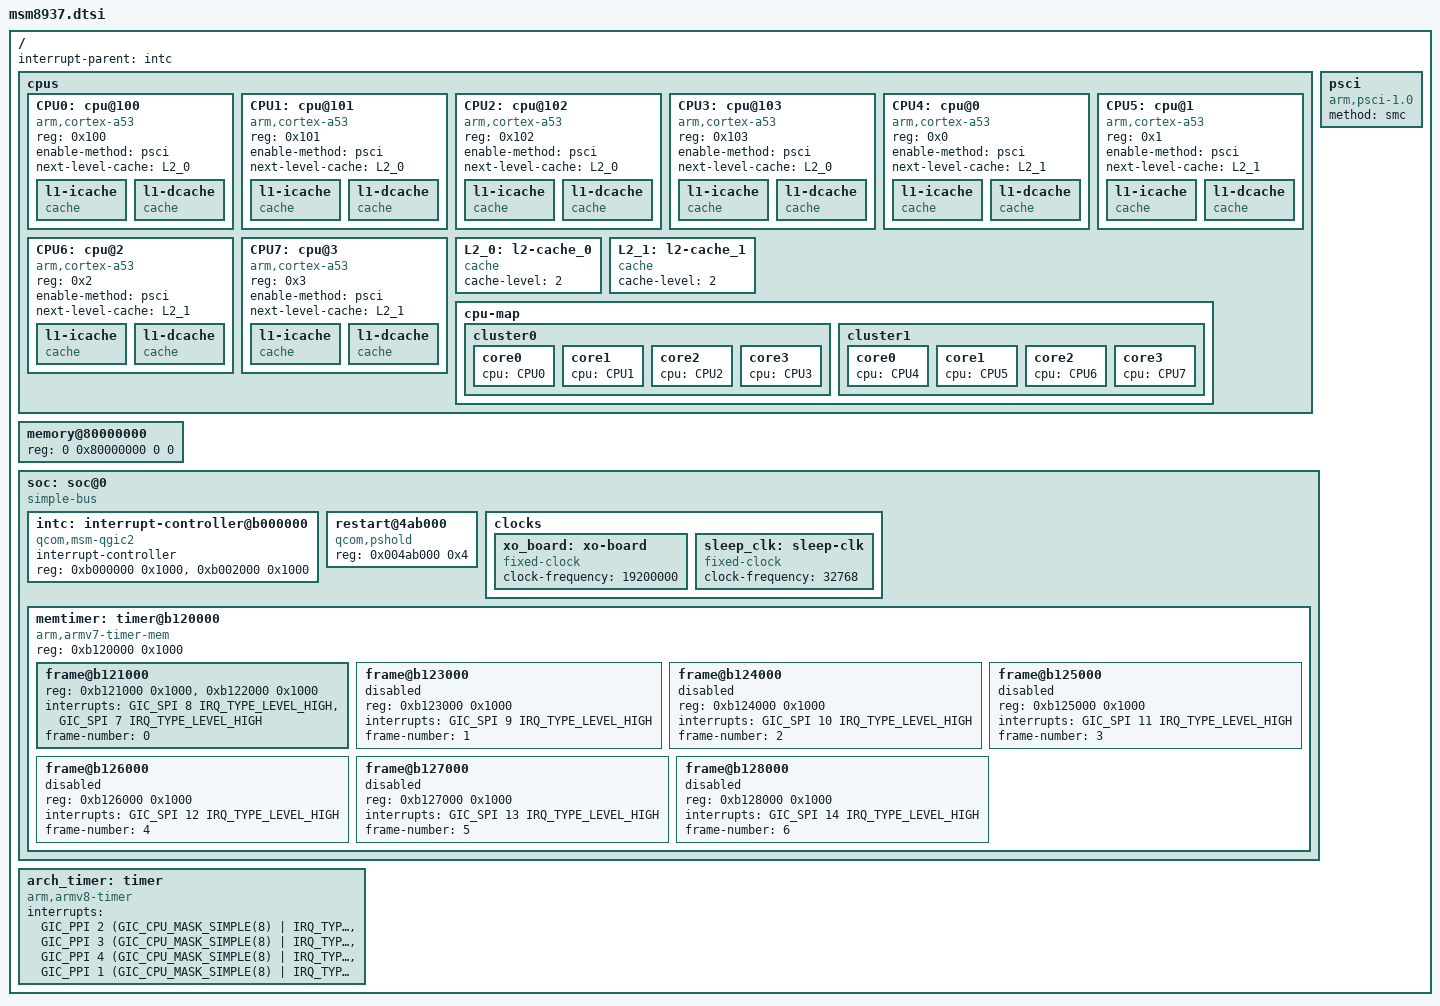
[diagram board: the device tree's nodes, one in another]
// SPDX-License-Identifier: BSD-3-Clause
/*
 * Copyright (c) 2023, Dang Huynh <danct12@riseup.net>
 */

#include <dt-bindings/interrupt-controller/arm-gic.h>

/ {
	interrupt-parent = <&intc>;

	#address-cells = <2>;
	#size-cells = <2>;

	cpus {
		#address-cells = <1>;
		#size-cells = <0>;

		CPU0: cpu@100 {
			device_type = "cpu";
			compatible = "arm,cortex-a53";
			reg = <0x100>;
			enable-method = "psci";
			next-level-cache = <&L2_0>;
			l1-icache {
				compatible = "cache";
			};
			l1-dcache {
				compatible = "cache";
			};
		};

		CPU1: cpu@101 {
			device_type = "cpu";
			compatible = "arm,cortex-a53";
			reg = <0x101>;
			enable-method = "psci";
			next-level-cache = <&L2_0>;
			l1-icache {
				compatible = "cache";
			};
			l1-dcache {
				compatible = "cache";
			};
		};

		CPU2: cpu@102 {
			device_type = "cpu";
			compatible = "arm,cortex-a53";
			reg = <0x102>;
			enable-method = "psci";
			next-level-cache = <&L2_0>;
			l1-icache {
				compatible = "cache";
			};
			l1-dcache {
				compatible = "cache";
			};
		};

		CPU3: cpu@103 {
			device_type = "cpu";
			compatible = "arm,cortex-a53";
			reg = <0x103>;
			enable-method = "psci";
			next-level-cache = <&L2_0>;
			l1-icache {
				compatible = "cache";
			};
			l1-dcache {
				compatible = "cache";
			};
		};

		CPU4: cpu@0 {
			device_type = "cpu";
			compatible = "arm,cortex-a53";
			reg = <0x0>;
			enable-method = "psci";
			next-level-cache = <&L2_1>;
			l1-icache {
				compatible = "cache";
			};
			l1-dcache {
				compatible = "cache";
			};
		};

		CPU5: cpu@1 {
			device_type = "cpu";
			compatible = "arm,cortex-a53";
			reg = <0x1>;
			enable-method = "psci";
			next-level-cache = <&L2_1>;
			l1-icache {
				compatible = "cache";
			};
			l1-dcache {
				compatible = "cache";
			};
		};

		CPU6: cpu@2 {
			device_type = "cpu";
			compatible = "arm,cortex-a53";
			reg = <0x2>;
			enable-method = "psci";
			next-level-cache = <&L2_1>;
			l1-icache {
				compatible = "cache";
			};
			l1-dcache {
				compatible = "cache";
			};
		};

		CPU7: cpu@3 {
			device_type = "cpu";
			compatible = "arm,cortex-a53";
			reg = <0x3>;
			enable-method = "psci";
			next-level-cache = <&L2_1>;
			l1-icache {
				compatible = "cache";
			};
			l1-dcache {
				compatible = "cache";
			};
		};

		L2_0: l2-cache_0 {
			compatible = "cache";
			cache-level = <2>;
		};

		L2_1: l2-cache_1 {
			compatible = "cache";
			cache-level = <2>;
		};

		cpu-map {
			cluster0 {
				core0 {
					cpu = <&CPU0>;
				};

				core1 {
					cpu = <&CPU1>;
				};

				core2 {
					cpu = <&CPU2>;
				};

				core3 {
					cpu = <&CPU3>;
				};
			};

			cluster1 {
				core0 {
					cpu = <&CPU4>;
				};

				core1 {
					cpu = <&CPU5>;
				};

				core2 {
					cpu = <&CPU6>;
				};

				core3 {
					cpu = <&CPU7>;
				};
			};
		};
	};

	memory@80000000 {
		device_type = "memory";
		/* We expect the bootloader to fill in the reg */
		reg = <0 0x80000000 0 0>;
	};

	psci {
		compatible = "arm,psci-1.0";
		method = "smc";
	};
/*
	reserved-memory {
		#address-cells = <2>;
		#size-cells = <2>;
		ranges;

		other_ext_mem: memory@85b00000 {
			reg = <0x0 0x85b00000 0x0 0xd00000>;
			no-map;
		};

		modem_mem: memory@86800000 {
			reg = <0x0 0x86800000 0x0 0x5000000>;
			no-map;
		};

		adsp_fw_mem: memory@8b800000 {
			reg = <0x0 0x8b800000 0x0 0x1100000>;
			no-map;
		};

		wcnss_fw_mem: memory@8c900000 {
			reg = <0x0 0x8c900000 0x0 0x700000>;
			no-map;
		};

		venus_mem: memory@8f800000 {
			reg = <0x0 0x8f800000 0x0 0x800000>;
			no-map;
		};

		secure_mem: memory@f9000000 {
			reg = <0x0 0xf9000000 0x0 0x7000000>;
			no-map;
		};

		qseecom_mem: memory@f8000000 {
			reg = <0x0 0xf8000000 0x0 0x1000000>;
			no-map;
		};

		adsp_mem: memory@f7c00000 {
			reg = <0x0 0xf7c00000 0x0 0x400000>;
			no-map;
		};

	};
*/
	soc: soc@0 {
		compatible = "simple-bus";
		#address-cells = <1>;
		#size-cells = <1>;
		ranges = <0 0 0 0xffffffff>;

		intc: interrupt-controller@b000000 {
			compatible = "qcom,msm-qgic2";
			interrupt-controller;
			#interrupt-cells = <3>;
			reg = <0xb000000 0x1000>, <0xb002000 0x1000>;
		};

		restart@4ab000 {
			compatible = "qcom,pshold";
			reg = <0x004ab000 0x4>;
		};

		clocks {
			xo_board: xo-board {
				compatible = "fixed-clock";
				#clock-cells = <0>;
				clock-frequency = <19200000>;
			};

			sleep_clk: sleep-clk {
				compatible = "fixed-clock";
				#clock-cells = <0>;
				clock-frequency = <32768>;
			};
		};

		memtimer: timer@b120000 {
			#address-cells = <1>;
			#size-cells = <1>;
			ranges;
			compatible = "arm,armv7-timer-mem";
			reg = <0xb120000 0x1000>;

			frame@b121000 {
				reg = <0xb121000 0x1000>,
				      <0xb122000 0x1000>;
				interrupts = <GIC_SPI 8 IRQ_TYPE_LEVEL_HIGH>,
					     <GIC_SPI 7 IRQ_TYPE_LEVEL_HIGH>;
				frame-number = <0>;
			};

			frame@b123000 {
				reg = <0xb123000 0x1000>;
				interrupts = <GIC_SPI 9 IRQ_TYPE_LEVEL_HIGH>;
				frame-number = <1>;
				status = "disabled";
			};

			frame@b124000 {
				reg = <0xb124000 0x1000>;
				interrupts = <GIC_SPI 10 IRQ_TYPE_LEVEL_HIGH>;
				frame-number = <2>;
				status = "disabled";
			};

			frame@b125000 {
				reg = <0xb125000 0x1000>;
				interrupts = <GIC_SPI 11 IRQ_TYPE_LEVEL_HIGH>;
				frame-number = <3>;
				status = "disabled";
			};

			frame@b126000 {
				reg = <0xb126000 0x1000>;
				interrupts = <GIC_SPI 12 IRQ_TYPE_LEVEL_HIGH>;
				frame-number = <4>;
				status = "disabled";
			};

			frame@b127000 {
				reg = <0xb127000 0x1000>;
				interrupts = <GIC_SPI 13 IRQ_TYPE_LEVEL_HIGH>;
				frame-number = <5>;
				status = "disabled";
			};

			frame@b128000 {
				reg = <0xb128000 0x1000>;
				interrupts = <GIC_SPI 14 IRQ_TYPE_LEVEL_HIGH>;
				frame-number = <6>;
				status = "disabled";
			};
		};
	};

	arch_timer: timer {
		compatible = "arm,armv8-timer";
		interrupts = <GIC_PPI 2 (GIC_CPU_MASK_SIMPLE(8) | IRQ_TYPE_LEVEL_LOW)>,
			     <GIC_PPI 3 (GIC_CPU_MASK_SIMPLE(8) | IRQ_TYPE_LEVEL_LOW)>,
			     <GIC_PPI 4 (GIC_CPU_MASK_SIMPLE(8) | IRQ_TYPE_LEVEL_LOW)>,
			     <GIC_PPI 1 (GIC_CPU_MASK_SIMPLE(8) | IRQ_TYPE_LEVEL_LOW)>;
	};
};
